AUTOSAR XML (schema 4-0-3)
package /AppSwComponent_Dcm/SwComponentType
  swc implementation App_Dcm_Implementation: behavior=InternalBehaviors_DiagnosticService
    code-descriptors:
      code Default
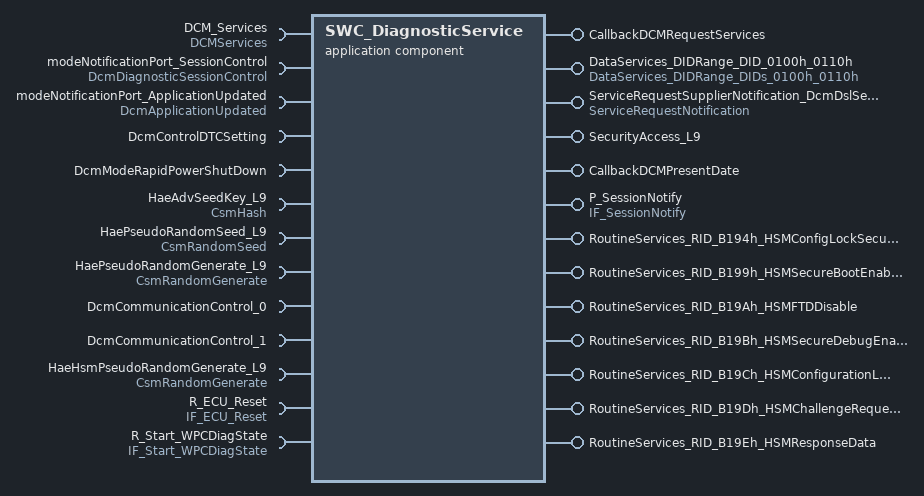
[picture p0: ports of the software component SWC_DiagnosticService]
  application sw component type SWC_DiagnosticService
    provide port CallbackDCMRequestServices: provided-com-specs=[{operation=StopProtocol, queue-length=1}, {operation=StartProtocol, queue-length=1}], provided-interface=CallbackDCMRequestServices
    require port DCM_Services: required-com-specs=[GetActiveProtocol, GetSecurityLevel, ResetToDefaultSession, GetSesCtrlType], required-interface=DCMServices
    provide port DataServices_DIDRange_DID_0100h_0110h: provided-interface=DataServices_DIDRange_DIDs_0100h_0110h
      provided-com-specs:
        operation=WriteDidData, queue-length=1
        operation=IsDidAvailable, queue-length=1
        operation=ReadDidData, queue-length=1
    provide port ServiceRequestSupplierNotification_DcmDslServiceRequestSupplierNotification0: provided-com-specs=[{operation=Indication, queue-length=1}, {operation=Confirmation, queue-length=1}], provided-interface=ServiceRequestNotification
    4 x require port:
      modeNotificationPort_SessionControl: mode-switch-receiver-com-spec{enhanced-mode-api=true, mode-group=DcmDiagnosticSessionControl, supports-asynchronous-mode-switch=true}, required-interface=DcmDiagnosticSessionControl
      modeNotificationPort_ApplicationUpdated: mode-switch-receiver-com-spec{enhanced-mode-api=true, mode-group=DcmApplicationUpdated, supports-asynchronous-mode-switch=true}, required-interface=DcmApplicationUpdated
      DcmControlDTCSetting: mode-switch-receiver-com-spec{enhanced-mode-api=true, mode-group=DcmControlDTCSetting, supports-asynchronous-mode-switch=true}, required-interface=DcmControlDTCSetting
      DcmModeRapidPowerShutDown: mode-switch-receiver-com-spec{enhanced-mode-api=true, mode-group=DcmModeRapidPowerShutDown, supports-asynchronous-mode-switch=true}, required-interface=DcmModeRapidPowerShutDown
    provide port SecurityAccess_L9: provided-com-specs=[{operation=CompareKey, queue-length=1}, {operation=GetSeed, queue-length=1}], provided-interface=SecurityAccess_L9
    require port HaeAdvSeedKey_L9: required-com-specs=[HashStart, HashUpdate, HashFinish], required-interface=CsmHash
    require port HaePseudoRandomSeed_L9: required-com-specs=[RandomSeedStart, RandomSeedUpdate, RandomSeedFinish], required-interface=CsmRandomSeed
    require port HaePseudoRandomGenerate_L9: client-com-spec=RandomGenerate, required-interface=CsmRandomGenerate
    provide port CallbackDCMPresentDate: server-com-spec{operation=GetPresentDate, queue-length=1}, provided-interface=CallbackDCMPresentDate
    require port DcmCommunicationControl_0: mode-switch-receiver-com-spec{enhanced-mode-api=true, mode-group=DcmCommunicationControl_0, supports-asynchronous-mode-switch=true}, required-interface=DcmCommunicationControl_0
    require port DcmCommunicationControl_1: mode-switch-receiver-com-spec{enhanced-mode-api=true, mode-group=DcmCommunicationControl_1, supports-asynchronous-mode-switch=true}, required-interface=DcmCommunicationControl_1
    require port HaeHsmPseudoRandomGenerate_L9: client-com-spec=RandomGenerate, required-interface=CsmRandomGenerate
    provide port P_SessionNotify: nonqueued-sender-com-spec=SR, provided-interface=IF_SessionNotify
    require port R_ECU_Reset: client-com-spec=CS, required-interface=IF_ECU_Reset
    require port R_Start_WPCDiagState: client-com-spec=CS, required-interface=IF_Start_WPCDiagState
    7 x provide port, all with server-com-spec{operation=Start, queue-length=1}:
      RoutineServices_RID_B194h_HSMConfigLockSecureDebug: provided-interface=RoutineServices_RID_B194h_HSMConfigLockSecureDebug
      RoutineServices_RID_B199h_HSMSecureBootEnable: provided-interface=RoutineServices_RID_B199h_HSMSecureBootEnable
      RoutineServices_RID_B19Ah_HSMFTDDisable: provided-interface=RoutineServices_RID_B19Ah_HSMFTDDisable
      RoutineServices_RID_B19Bh_HSMSecureDebugEnable: provided-interface=RoutineServices_RID_B19Bh_HSMSecureDebugEnable
      RoutineServices_RID_B19Ch_HSMConfigurationLockEnable: provided-interface=RoutineServices_RID_B19Ch_HSMConfigurationLockEnable
      RoutineServices_RID_B19Dh_HSMChallengeRequest: provided-interface=RoutineServices_RID_B19Dh_HSMChallengeRequest
      RoutineServices_RID_B19Eh_HSMResponseData: provided-interface=RoutineServices_RID_B19Eh_HSMResponseData
    behavior InternalBehaviors_DiagnosticService: data-type-mapping=DcmApplicationUpdated
      4 x operation invoked event:
        OIE_CallbackDCMRequestServices_StopProtocol: start-on-event=CallbackDCMRequestServices_StopProtocol, operation=CallbackDCMRequestServices.StopProtocol
        OIE_CallbackDCMRequestServices_StartProtocol: start-on-event=CallbackDCMRequestServices_StartProtocol, operation=CallbackDCMRequestServices.StartProtocol
        OIE_ServiceRequestSupplierNotification_Indication: start-on-event=ServiceRequestSupplierNotification_Indication, operation=ServiceRequestSupplierNotification_DcmDslServiceRequestSupplierNotification0.Indication
        OIE_ServiceRequestSupplierNotification_Confirmation: start-on-event=ServiceRequestSupplierNotification_Confirmation, operation=ServiceRequestSupplierNotification_DcmDslServiceRequestSupplierNotification0.Confirmation
      4 x swc mode switch event, all with activation=ON-ENTRY:
        SMSE_Entry_DiagnosticSessionControlNotification_modeNotificationPort_SessionControl_DcmDiagnosticSessionControl_DCM_DEFAULT_SESSION: start-on-event=DiagnosticSessionControlNotification, mode=modeNotificationPort_SessionControl.DcmDiagnosticSessionControl.DCM_DEFAULT_SESSION
        SMSE_Entry_DiagnosticSessionControlNotification_modeNotificationPort_SessionControl_DcmDiagnosticSessionControl_DCM_EXTENDED_DIAGNOSTIC_SESSION: start-on-event=DiagnosticSessionControlNotification, mode=modeNotificationPort_SessionControl.DcmDiagnosticSessionControl.DCM_EXTENDED_DIAGNOSTIC_SESSION
        SMSE_ApplicationUpdatedIndication_modeNotificationPort_ApplicationUpdated_DcmApplicationUpdated_APP_UPDATED: start-on-event=ApplicationUpdatedIndication, mode=modeNotificationPort_ApplicationUpdated.DcmApplicationUpdated.APP_UPDATED
        SMSE_ApplicationUpdatedIndication_modeNotificationPort_ApplicationUpdated_DcmApplicationUpdated_APP_NOT_UPDATED: start-on-event=ApplicationUpdatedIndication, mode=modeNotificationPort_ApplicationUpdated.DcmApplicationUpdated.APP_NOT_UPDATED
      10 x operation invoked event:
        OIE_L9_CompareKey: start-on-event=L9_CompareKey, operation=SecurityAccess_L9.CompareKey
        OIE_L9_GetSeed: start-on-event=L9_GetSeed, operation=SecurityAccess_L9.GetSeed
        OIE_CallbackDCMPresentDate_GetPresentDate: start-on-event=CallbackDCMPresentDate_GetPresentDate, operation=CallbackDCMPresentDate.GetPresentDate
        OIE_RE_RID_B194h_HSMConfigLockSecureDebug_Start_RoutineServices_RID_B194h_HSMConfigLockSecureDebug_Start: start-on-event=RE_RID_B194h_HSMConfigLockSecureDebug_Start, operation=RoutineServices_RID_B194h_HSMConfigLockSecureDebug.Start
        OIE_RE_RID_B199h_HSMSecureBootEnable_Start_RoutineServices_RID_B199h_HSMSecureBootEnable_Start: start-on-event=RE_RID_B199h_HSMSecureBootEnable_Start, operation=RoutineServices_RID_B199h_HSMSecureBootEnable.Start
        OIE_RE_RID_B19Ah_HSMFTDDisable_Start_RoutineServices_RID_B19Ah_HSMFTDDisable_Start: start-on-event=RE_RID_B19Ah_HSMFTDDisable_Start, operation=RoutineServices_RID_B19Ah_HSMFTDDisable.Start
        OIE_RE_RID_B19Bh_HSMSecureDebugEnable_Start_RoutineServices_RID_B19Bh_HSMSecureDebugEnable_Start: start-on-event=RE_RID_B19Bh_HSMSecureDebugEnable_Start, operation=RoutineServices_RID_B19Bh_HSMSecureDebugEnable.Start
        OIE_RE_RID_B19Ch_HSMConfigurationLockEnable_Start_RoutineServices_RID_B19Ch_HSMConfigurationLockEnable_Start: start-on-event=RE_RID_B19Ch_HSMConfigurationLockEnable_Start, operation=RoutineServices_RID_B19Ch_HSMConfigurationLockEnable.Start
        OIE_RE_RID_B19Dh_HSMChallengeRequest_Start_RoutineServices_RID_B19Dh_HSMChallengeRequest_Start: start-on-event=RE_RID_B19Dh_HSMChallengeRequest_Start, operation=RoutineServices_RID_B19Dh_HSMChallengeRequest.Start
        OIE_RE_RID_B19Eh_HSMResponseData_Start_RoutineServices_RID_B19Eh_HSMResponseData_Start: start-on-event=RE_RID_B19Eh_HSMResponseData_Start, operation=RoutineServices_RID_B19Eh_HSMResponseData.Start
      17 x runnable:
        CallbackDCMRequestServices_StopProtocol: can-be-invoked-concurrently=true, symbol=AppDcm_StopProtocol
        CallbackDCMRequestServices_StartProtocol: can-be-invoked-concurrently=true, symbol=AppDcm_StartProtocol
        DO_NOT_REMOVE: can-be-invoked-concurrently=true, symbol=AppDcm_Runnable
          4 x sync call:
            SSCP_GetActiveProtocol: operation=DCM_Services.GetActiveProtocol
            SSCP_GetSecurityLevel: operation=DCM_Services.GetSecurityLevel
            SSCP_ResetToDefaultSession: operation=DCM_Services.ResetToDefaultSession
            SSCP_GetSesCtrlType: operation=DCM_Services.GetSesCtrlType
        ServiceRequestSupplierNotification_Indication: can-be-invoked-concurrently=true
        ServiceRequestSupplierNotification_Confirmation: can-be-invoked-concurrently=true
          sync call SSCP_ServiceRequestSupplierNotification_Confirmation_R_Start_WPCDiagState_CS: operation=R_Start_WPCDiagState.CS
        DiagnosticSessionControlNotification: can-be-invoked-concurrently=true, symbol=AppDcm_DiagnosticSessionControlNotification
          data-send-points:
            access DSP_DiagnosticSessionControlNotification_P_SessionNotify_SR: accessed-variable=P_SessionNotify.SR, scope=COMMUNICATION-INTER-ECU
          mode-access-point mode-group=modeNotificationPort_SessionControl.DcmDiagnosticSessionControl:
            ident MRAP_DiagnosticSessionControlNotification_modeNotificationPort_SessionControl_DcmDiagnosticSessionControl
        ApplicationUpdatedIndication: can-be-invoked-concurrently=true
          mode-access-point mode-group=modeNotificationPort_ApplicationUpdated.DcmApplicationUpdated:
            ident MRAP_ApplicationUpdatedIndication_modeNotificationPort_ApplicationUpdated_DcmApplicationUpdated
        L9_CompareKey: can-be-invoked-concurrently=true, symbol=AppDcm_CompareKey_L9
          sync call SSCP_HaeAdvSeedKeyStart_L9: operation=HaeAdvSeedKey_L9.HashStart
          sync call SSCP_HaeAdvSeedKeyUpdate_L9: operation=HaeAdvSeedKey_L9.HashUpdate
          sync call SSCP_HaeAdvSeedKeyFinish_L9: operation=HaeAdvSeedKey_L9.HashFinish
        L9_GetSeed: can-be-invoked-concurrently=true, symbol=AppDcm_GetSeed_L9
          5 x sync call:
            SSCP_HaePseudoRandomSeedStart_L9: operation=HaePseudoRandomSeed_L9.RandomSeedStart
            SSCP_HaePseudoRandomSeedUpdate_L9: operation=HaePseudoRandomSeed_L9.RandomSeedUpdate
            SSCP_HaePseudoRandomSeedFinish_L9: operation=HaePseudoRandomSeed_L9.RandomSeedFinish
            SSCP_HaePseudoRandomGenerate_L9: operation=HaePseudoRandomGenerate_L9.RandomGenerate
            SSCP_L9_GetSeed_HaeHsmPseudoRandomGenerate_L9_RandomGenerate: operation=HaeHsmPseudoRandomGenerate_L9.RandomGenerate
        CallbackDCMPresentDate_GetPresentDate: can-be-invoked-concurrently=true, symbol=AppDcm_GetPresentDate
        RE_RID_B194h_HSMConfigLockSecureDebug_Start: symbol=RID_B194h_HSMConfigLockSecureDebug_Start
        RE_RID_B199h_HSMSecureBootEnable_Start: symbol=RID_B199h_HSMSecureBootEnable_Start
        RE_RID_B19Ah_HSMFTDDisable_Start: symbol=RID_B19Ah_HSMFTDDisable_Start
        RE_RID_B19Bh_HSMSecureDebugEnable_Start: symbol=RID_B19Bh_HSMSecureDebugEnable_Start
        RE_RID_B19Ch_HSMConfigurationLockEnable_Start: symbol=RID_B19Ch_HSMConfigurationLockEnable_Start
        RE_RID_B19Dh_HSMChallengeRequest_Start: symbol=RID_B19Dh_HSMChallengeRequest_Start
        RE_RID_B19Eh_HSMResponseData_Start: symbol=RID_B19Eh_HSMResponseData_Start
      swc service dependency SwcServiceDependency0
        assigned-ports:
          port-prototype=modeNotificationPort_SessionControl, role=Custom
          port-prototype=modeNotificationPort_ApplicationUpdated, role=Custom
          port-prototype=DcmControlDTCSetting, role=Custom
          port-prototype=DcmModeRapidPowerShutDown, role=Custom
          port-prototype=DcmCommunicationControl_0, role=Custom
          port-prototype=DcmCommunicationControl_1, role=Custom
        service-needs:
          bsw mgr needs BswMgrNeeds
package /AppSwComponent_Dcm/diag_interface
  sender receiver interface IF_SessionNotify
    data SR: type=uint8
  client server interface IF_ECU_Reset
    operation CS: possible-error=[Response_Fail, Response_Success]
    error Response_Fail: error-code=1
    error Response_Success: error-code=2
